# gcr_me30 register map
Registers are access not given, no defined reset value unless marked. A register's access mark holds for its fields unless they carry their own. Offsets are from the block's base; lines under a group give offsets from that group; [hi:lo] are bit positions; {n}, {i} and the like mark numbered series; 'fields as' and 'values as' point back to an identical list; <NAME> marks a mode.

## Memory map
0x40000000 GCR size 0x400 — Global Control Registers.

## GCR — Global Control Registers.
Base 0x40000000
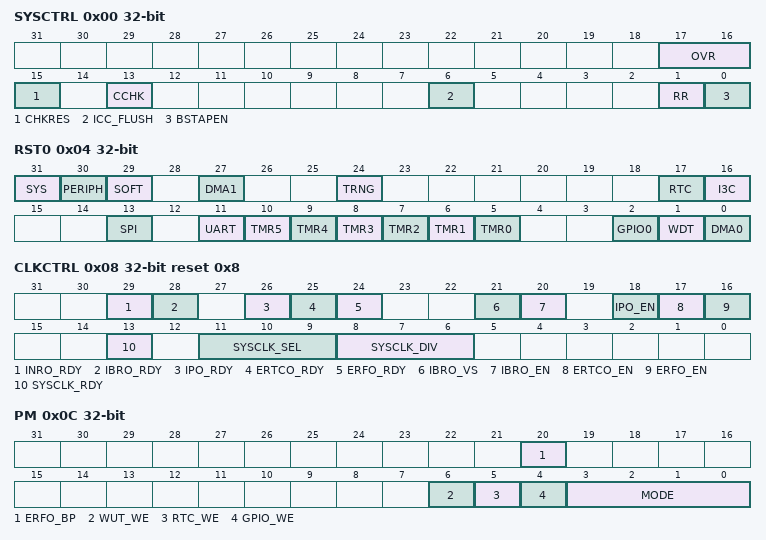
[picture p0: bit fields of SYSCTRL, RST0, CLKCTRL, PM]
0x00 SYSCTRL — System Control.
  [17:16] OVR — Operating Voltage Range.
  [15] CHKRES ro — ROM Checksum Result. This bit is only valid when the checksum is done and CCHK0 bit is cleared.
    0=pass (ROM Checksum Correct.); 1=fail (ROM Checksum Fail.)
  [13] CCHK — Compute ROM Checksum. This bit is self-cleared when calculation is completed. Once set, software clearing this bit is ignored and the bit will remain set until the operation is completed.
    0=complete (No operation/complete.); 1=Start operation
  [6] ICC_FLUSH — Code Cache Flush. This bit is used to flush the code caches and the instruction buffer of the Cortex-M33.
    0=Normal Code Cache Operation; 1=flush (Code Caches and CPU instruction buffer are flushed)
  [1] RR — ROM Redundancy Enable.
  [0] BSTAPEN — Boundary Scan TAP Enable. When enabled, the JTAG port is connected to the Boundary Scan TAP instead of the ARM ICE.
0x04 RST0 — Reset.
  [31] SYS — System Reset. Setting this bit to 1 resets the CPU core and all peripherals, including the watchdog timer.
  [30] PERIPH — Peripheral Reset. Setting this bit to 1 resets all peripherals. The CPU core, the watchdog timer, and all GPIO pins are unaffected by this reset.
  [29] SOFT — Soft Reset. Setting this bit to 1 resets everything except the CPU and the watchdog timer.
  [27] DMA1 — DMA1 Reset.
  [24] TRNG — TRNG Reset.
  [17] RTC — Real Time Clock Reset.
  [16] I3C — I3C Reset.
  [13] SPI — SPI Reset.
  [11] UART — UART Reset.
  [n+5] TMR{n} (n=0..5) — Timer{n} Reset.
  [2] GPIO0 — GPIO0 Reset. Setting this bit to 1 resets GPIO0 pins to their default states.
  [1] WDT — Watchdog Timer Reset.
  [0] DMA0 — DMA Reset.
0x08 CLKCTRL reset 0x8 — Clock Control.
  [29] INRO_RDY ro — Internal Nano Ring Oscillator Low Frequency Reference Clock Ready.
    0=not (Is not Ready.); 1=ready (Is Ready.)
  [28] IBRO_RDY ro — Internal Baud Rate Oscillator Ready.
    0=not (Is not Ready.); 1=ready (Is Ready.)
  [26] IPO_RDY ro — Internal Primary Oscillator Ready.
    0=not (Is not Ready.); 1=ready (Is Ready.)
  [25] ERTCO_RDY ro — 32kHz Crystal Oscillator Ready
    0=not (Is not Ready.); 1=ready (Is Ready.)
  [24] ERFO_RDY ro — 27MHz Crystal Oscillator Ready
    0=not (Is not Ready.); 1=ready (Is Ready.)
  [21] IBRO_VS — 7.3728MHz Internal Oscillator Voltage Source Select
  [20] IBRO_EN — 8MHz High Frequency Internal Reference Clock Enable.
  [18] IPO_EN — 50MHz High Frequency Internal Reference Clock Enable.
  [17] ERTCO_EN — 32kHz Crystal Oscillator Enable.
  [16] ERFO_EN — 27MHz Crystal Oscillator Enable.
    0=dis (Is Disabled.); 1=en (Is Enabled.)
  [13] SYSCLK_RDY ro — Clock Ready. This read only bit reflects whether the currently selected system clock source is running.
    0=busy (Switchover to the new clock source (as selected by CLKSEL) has not yet occurred.); 1=ready (System clock running from CLKSEL clock source.)
  [11:9] SYSCLK_SEL — Clock Source Select. This 3 bit field selects the source for the system clock.
    0=IPO (The internal Primary oscillator is used for the system clock.); 2=ERFO (27MHz Crystal is used for the system clock.); 3=INRO (8kHz Internal Nano Ring Oscillator is used for the system clock.); 5=IBRO (The internal Baud Rate oscillator is used for the system clock.); 6=ERTCO (32kHz is used for the system clock.); 7=EXTCLK (External Clock.)
  [8:6] SYSCLK_DIV — Prescaler Select. This 3-bit field sets the system operating frequency by controlling the prescaler that divides the output of the system clock source.
    0=div1 (Divide by 1.); 1=div2 (Divide by 2.); 2=div4 (Divide by 4.); 3=div8 (Divide by 8.); 4=div16 (Divide by 16.); 5=div32 (Divide by 32.); 6=div64 (Divide by 64.); 7=div128 (Divide by 128.)
0x0C PM — Power Management.
  [20] ERFO_BP — XTAL Bypass
    0=normal; 1=bypass
  [6] WUT_WE — Enable Wakeup Timer as wakeup source.
  [5] RTC_WE — RTC Alarm Wake Up Enable. This bit enables RTC alarm as wakeup source. If enabled, the desired RTC alarm must be configured via the RTC control registers.
  [4] GPIO_WE — GPIO Wake Up Enable. This bit enables all GPIO pins as potential wakeup sources. Any GPIO configured for wakeup is capable of causing an exit from IDLE or STANDBY modes when this bit is set.
  [3:0] MODE — Operating Mode. This 4-bit field selects the current operating mode for the device. Note that code execution only occurs during ACTIVE mode.
    0=ACTIVE (Active Mode.); 4=BACKUP (Backup Mode.); 10=PDM (DeepSleep Mode.)
0x18 PCLKDIV — Peripheral Clock Divider.
  [31:0] CLKDIV — Clock Divide Value.
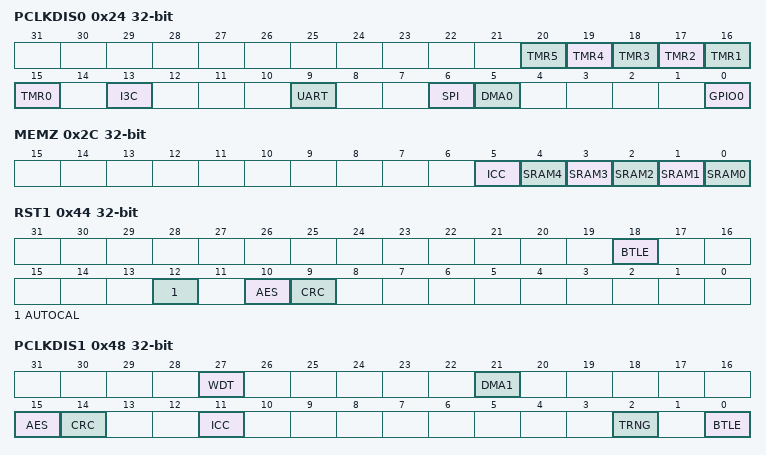
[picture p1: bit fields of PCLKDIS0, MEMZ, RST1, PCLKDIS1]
0x24 PCLKDIS0 — Peripheral Clock Disable.
  [all] fields
    0=en (enable it.); 1=dis (disable it.)
  [n+15] TMR{n} (n=0..5) — Timer {n} Disable.
  [13] I3C — I3C Disable.
  [9] UART — UART Disable.
  [6] SPI — SPI Disable.
  [5] DMA0 — DMA0 Disable.
  [0] GPIO0 — GPIO0 Clock Disable.
0x28 MEMCTRL — Memory Clock Control Register.
  [2:0] FWS — Flash Wait State. These bits define the number of wait-state cycles per Flash data read access. Minimum wait state is 2.
0x2C MEMZ — Memory Zeroize Control.
  [all] fields
    0=nop (No operation/complete.); 1=Start operation
  [5] ICC — Internal Cache.
  [n] SRAM{n} (n=0..4) — System RAM Block {n}.
0x40 SYSST ro — System Status Register.
  [0] ICELOCK — ARM ICE Lock Status.
    0=unlocked (ICE is unlocked.); 1=locked (ICE is locked.)
0x44 RST1 — Reset 1.
  [18] BTLE — BTLE Reset.
  [12] AUTOCAL — Auto calibration Reset.
  [10] AES — AES Reset.
  [9] CRC — CRC Reset.
0x48 PCLKDIS1 — Peripheral Clock Disable.
  [all] fields
    0=en (Enable.); 1=dis (Disable.)
  [27] WDT — WDT Clock Disable
  [21] DMA1 — DMA1 Clock Disable
  [15] AES — AES Clock Disable
  [14] CRC — CRC Disable.
  [11] ICC — ICC Clock Disable.
  [2] TRNG — TRNG Clock Disable.
  [0] BTLE — BTLE Clock Disable.
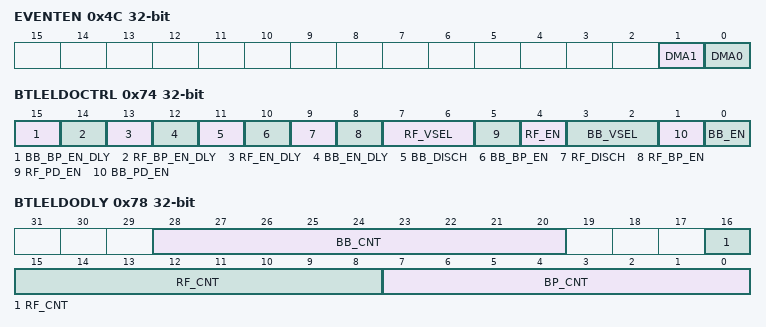
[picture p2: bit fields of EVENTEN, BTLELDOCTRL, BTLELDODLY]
0x4C EVENTEN — Event Enable Register.
  [1] DMA1 — Enable DMA1 event. When this bit is set, a DMA1 event will cause an RXEV event to wake the CPU from WFE sleep mode.
  [0] DMA0 — Enable DMA0 event. When this bit is set, a DMA0 event will cause an RXEV event to wake the CPU from WFE sleep mode.
0x50 REVISION ro
  [15:0] REVISION — Manufacturer Chip Revision.
0x54 SYSINTEN — System Status Interrupt Enable Register.
  [0] ICEUNLOCK — ARM ICE Unlock Interrupt Enable.
    0=dis (disabled.); 1=en (enabled.)
0x64 ECCERR — ECC Error Register
  [0] FLASH write-1-clears — ECC Flash Error Flag. Write 1 to clear.
0x68 ECCCED — ECC Correctable Error Detect Register.
  [0] FLASH write-1-clears — ECC Correctable Error Detect Flag for Flash. Write 1 to clear.
0x6C ECCINTEN — ECC Interrupt Enable Register
  [0] FLASH — ECC Flash0 Interrupt Enable.
0x70 ECCADDR ro — ECC Error Address Register
  [31:0] ECCADDR — Flash byte address of the most recent ECC event. Bits [1:0] are always zero (word-aligned).
0x74 BTLELDOCTRL — BTLE LDO Control Register
  [15] BB_BP_EN_DLY ro — LDO BB Bypass Enable Delay Status.
  [14] RF_BP_EN_DLY ro — LDO RF Bypass Enable Delay Status.
  [13] RF_EN_DLY ro — LDO RF Enable Delay Status.
  [12] BB_EN_DLY ro — LDO BB Enable Delay Status.
  [11] BB_DISCH — LDO BB Discharge.
  [10] BB_BP_EN — LDO BB Bypass Enable.
  [9] RF_DISCH — LDO RF Discharge.
  [8] RF_BP_EN — LDO RF Bypass Enable.
  [7:6] RF_VSEL — LDO RF Voltage Setting.
    0=0_9 (0.9V); 1=1.0V; 2=1.1V; 3=1_2 (1.2V)
  [5] RF_PD_EN — LDO RF Pull DOwn.
  [4] RF_EN — LDO RF enable.
  [3:2] BB_VSEL — Voltage Selection for BB LDO.
    0=0_9 (0.9V); 1=1.0V; 2=1.1V; 3=1_2 (1.2V)
  [1] BB_PD_EN — LDO BB Pull Down.
  [0] BB_EN — LDO BB enable.
0x78 BTLELDODLY — BTLE LDO Delay Register
  [28:20] BB_CNT — BB LDO delay count.
  [16:8] RF_CNT — RF LDO delay count.
  [7:0] BP_CNT — Bypass delay count.
0x80 GPR — General Purpose Register 0.
